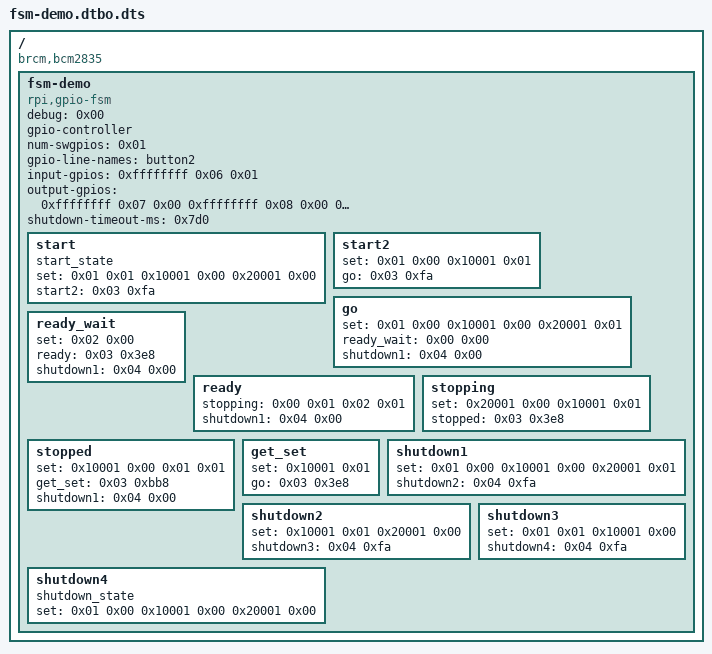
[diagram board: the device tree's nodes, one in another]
/dts-v1/;

/ {
	compatible = "brcm,bcm2835";

	fragment@0 {
		target-path = "/";

		__overlay__ {

			fsm-demo {
				compatible = "rpi,gpio-fsm";
				debug = <0x00>;
				gpio-controller;
				#gpio-cells = <0x02>;
				num-swgpios = <0x01>;
				gpio-line-names = "button2";
				input-gpios = <0xffffffff 0x06 0x01>;
				output-gpios = <0xffffffff 0x07 0x00 0xffffffff 0x08 0x00 0xffffffff 0x19 0x00>;
				shutdown-timeout-ms = <0x7d0>;
				phandle = <0x01>;

				start {
					start_state;
					set = <0x01 0x01 0x10001 0x00 0x20001 0x00>;
					start2 = <0x03 0xfa>;
				};

				start2 {
					set = <0x01 0x00 0x10001 0x01>;
					go = <0x03 0xfa>;
				};

				go {
					set = <0x01 0x00 0x10001 0x00 0x20001 0x01>;
					ready_wait = <0x00 0x00>;
					shutdown1 = <0x04 0x00>;
				};

				ready_wait {
					set = <0x02 0x00>;
					ready = <0x03 0x3e8>;
					shutdown1 = <0x04 0x00>;
				};

				ready {
					stopping = <0x00 0x01 0x02 0x01>;
					shutdown1 = <0x04 0x00>;
				};

				stopping {
					set = <0x20001 0x00 0x10001 0x01>;
					stopped = <0x03 0x3e8>;
				};

				stopped {
					set = <0x10001 0x00 0x01 0x01>;
					get_set = <0x03 0xbb8>;
					shutdown1 = <0x04 0x00>;
				};

				get_set {
					set = <0x10001 0x01>;
					go = <0x03 0x3e8>;
				};

				shutdown1 {
					set = <0x01 0x00 0x10001 0x00 0x20001 0x01>;
					shutdown2 = <0x04 0xfa>;
				};

				shutdown2 {
					set = <0x10001 0x01 0x20001 0x00>;
					shutdown3 = <0x04 0xfa>;
				};

				shutdown3 {
					set = <0x01 0x01 0x10001 0x00>;
					shutdown4 = <0x04 0xfa>;
				};

				shutdown4 {
					shutdown_state;
					set = <0x01 0x00 0x10001 0x00 0x20001 0x00>;
				};
			};
		};
	};

	__overrides__ {
		fsm_debug = <0x01 0x64656275 0x673a3000>;
	};

	__symbols__ {
		fsm_demo = "/fragment@0/__overlay__/fsm-demo";
	};

	__fixups__ {
		gpio = "/fragment@0/__overlay__/fsm-demo:input-gpios:0\0/fragment@0/__overlay__/fsm-demo:output-gpios:0\0/fragment@0/__overlay__/fsm-demo:output-gpios:12\0/fragment@0/__overlay__/fsm-demo:output-gpios:24";
	};

	__local_fixups__ {

		__overrides__ {
			fsm_debug = <0x00>;
		};
	};
};
